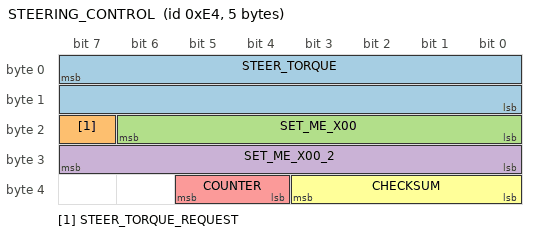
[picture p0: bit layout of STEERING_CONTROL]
BO_ 228 STEERING_CONTROL: 5 ADAS
 SG_ STEER_TORQUE : 7|16@0- (1,0) [-3840|3840] "" EPS
 SG_ STEER_TORQUE_REQUEST : 23|1@0+ (1,0) [0|1] "" EPS
 SG_ SET_ME_X00 : 22|7@0+ (1,0) [0|127] "" EPS
 SG_ SET_ME_X00_2 : 31|8@0+ (1,0) [0|0] "" EPS
 SG_ COUNTER : 37|2@0+ (1,0) [0|3] "" EPS
 SG_ CHECKSUM : 35|4@0+ (1,0) [0|15] "" EPS
